# ADuCM320i register map
Vendor: Analog Devices Inc.; Series: ARMCM3; File version: 1.0
CPU: CM3 r2p1, little endian, no MPU, no FPU, 3 interrupt priority bits
Registers are 16-bit, read-write, no defined reset value unless marked. A register's access mark holds for its fields unless they carry their own. Offsets are from the block's base; [hi:lo] are bit positions.

## MDIO — MDIO Interface
Base 0x40005C00
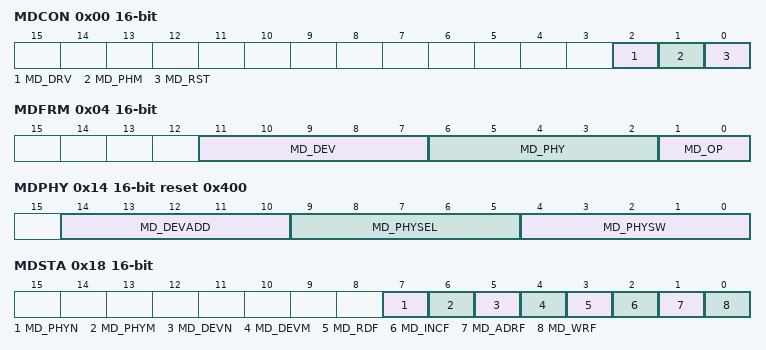
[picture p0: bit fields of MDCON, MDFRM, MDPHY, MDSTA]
0x00 MDCON — MDIO block control
  [2] MD_DRV
    0=MD_DRV_OD (MDIO drive open drain.); 1=MD_DRV_PP (MDIO drive push-pull.)
  [1] MD_PHM range 0x00000000..0x00000001
  [0] MD_RST wo range 0x00000000..0x00000001
0x04 MDFRM ro — MDIO received frame control information
  [11:7] MD_DEV range 0x00000000..0x0000001F
  [6:2] MD_PHY range 0x00000000..0x0000001F
  [1:0] MD_OP
    0=MD_OP_ADF (Address frame.); 1=MD_OP_WRF (Write frame.); 2=MD_OP_INCF (PostReadIncAdd frame.); 3=MD_OP_RDF (Read frame.)
0x08 MDRXD ro — MDIO received data
  [15:0] MD_RXD range 0x00000000..0x0000FFFF
0x0C MDADR ro — MDIO received address
  [15:0] MD_ADR range 0x00000000..0x0000FFFF
0x10 MDTXD — MDIO data for transmission
  [15:0] MD_TXD range 0x00000000..0x0000FFFF
0x14 MDPHY reset 0x400 (reset mask 0x0) — MDIO PHYADDR software values and selection and DEVADD
  [14:10] MD_DEVADD range 0x00000000..0x0000001F, [9:5] MD_PHYSEL range 0x00000000..0x0000001F, [4:0] MD_PHYSW range 0x00000000..0x0000001F
0x18 MDSTA — MDIO progress signaling through frame
  [7] MD_PHYN ro range 0x00000000..0x00000001, [6] MD_PHYM ro range 0x00000000..0x00000001, [5] MD_DEVN ro range 0x00000000..0x00000001, [4] MD_DEVM ro range 0x00000000..0x00000001, [3] MD_RDF ro range 0x00000000..0x00000001, [2] MD_INCF ro range 0x00000000..0x00000001, [1] MD_ADRF ro range 0x00000000..0x00000001, [0] MD_WRF ro range 0x00000000..0x00000001
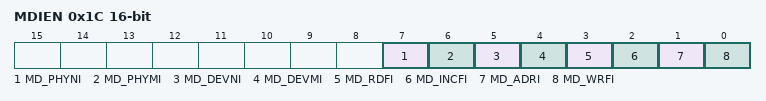
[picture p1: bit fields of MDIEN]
0x1C MDIEN — MDIO interrupt enables
  [7] MD_PHYNI range 0x00000000..0x00000001, [6] MD_PHYMI range 0x00000000..0x00000001, [5] MD_DEVNI range 0x00000000..0x00000001, [4] MD_DEVMI range 0x00000000..0x00000001, [3] MD_RDFI range 0x00000000..0x00000001, [2] MD_INCFI range 0x00000000..0x00000001, [1] MD_ADRI range 0x00000000..0x00000001, [0] MD_WRFI range 0x00000000..0x00000001
0x20 MDPIN — MDIO read PHYADDR pins
  [4:0] MD_PIN ro range 0x00000000..0x0000001F

## DMA — Direct Memory Access
Base 0x40010000
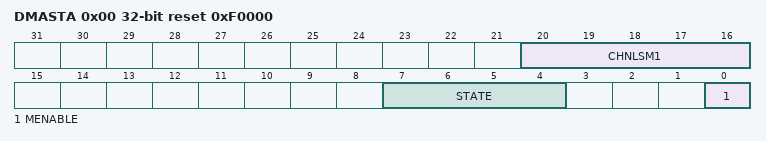
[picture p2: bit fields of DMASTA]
0x00 DMASTA 32-bit ro reset 0xF0000 (reset mask 0x0) — DMA Status
  [20:16] CHNLSM1 range 0x00000000..0x0000001F — Number of available DMA channels minus 1
  [7:4] STATE range 0x00000000..0x0000000F — Current state of DMA controller
  [0] MENABLE range 0x00000000..0x00000001 — Enable status of the controller
0x04 DMACFG 32-bit wo — DMA Configuration
  [0] MENABLE range 0x00000000..0x00000001 — Controller enable
0x08 DMAPDBPTR 32-bit — DMA channel primary control data base pointer
  [31:0] CTRLBASEPTR range 0x00000000..0xFFFFFFFF — Pointer to the base address of the primary data structure
0x0C DMAADBPTR 32-bit ro reset 0x100 (reset mask 0x0) — DMA channel alternate control data base pointer
  [31:0] ALTCBPTR range 0x00000000..0xFFFFFFFF — Base address of the alternate data structure
0x14 DMASWREQ 32-bit wo — DMA channel software request
  [13:0] CHSWREQ range 0x00000000..0x00003FFF — Generate software request
0x20 DMARMSKSET 32-bit — DMA channel request mask set
  [13:0] CHREQMSET range 0x00000000..0x00003FFF — Mask requests from DMA channels
0x24 DMARMSKCLR 32-bit wo — DMA channel request mask clear
  [13:0] CHREQMCLR range 0x00000000..0x00003FFF — Clear REQ_MASK_SET bits in DMARMSKSET
0x28 DMAENSET 32-bit — DMA channel enable set
  [13:0] CHENSET range 0x00000000..0x00003FFF — Enable DMA channels
0x2C DMAENCLR 32-bit wo — DMA channel enable clear
  [13:0] CHENCLR range 0x00000000..0x00003FFF — Disable DMA channels
0x30 DMAALTSET 32-bit — DMA channel primary-alternate set
  [13:0] CHPRIALTSET range 0x00000000..0x00003FFF — Control struct status / select alt struct
0x34 DMAALTCLR 32-bit wo — DMA channel primary-alternate clear
  [13:0] CHPRIALTCLR range 0x00000000..0x00003FFF — Select primary data struct
0x38 DMAPRISET 32-bit — DMA channel priority set
  [13:0] CHPRISET range 0x00000000..0x00003FFF — Configure channel for high priority
0x3C DMAPRICLR 32-bit wo — DMA channel priority clear
  [13:0] CHPRICLR range 0x00000000..0x00003FFF — Configure channel for default priority level
0x4C DMAERRCLR 32-bit — DMA Per Channel Bus Error
  [13:0] ERRCLR range 0x00000000..0x00003FFF — Bus error status
0x800 DMABSSET 32-bit — DMA channel bytes swap enable set
  [13:0] CHBSWAPSET range 0x00000000..0x00003FFF — Byte swap status
0x804 DMABSCLR 32-bit wo — DMA channel bytes swap enable clear
  [13:0] CHBSWAPCLR range 0x00000000..0x00003FFF — Disable byte swap
